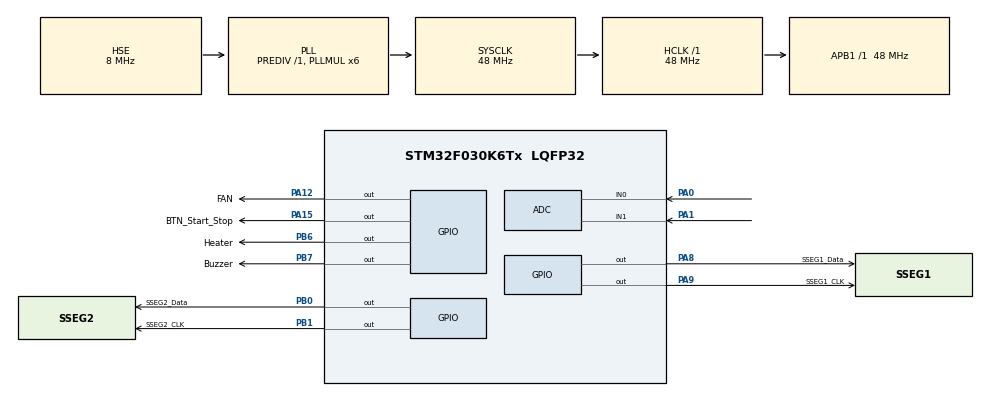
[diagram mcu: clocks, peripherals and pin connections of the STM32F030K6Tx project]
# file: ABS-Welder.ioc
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ADC.ContinuousConvMode=ENABLE
ADC.SamplingTime=ADC_SAMPLETIME_71CYCLES_5
Dma.ADC.0.Direction=DMA_PERIPH_TO_MEMORY
Dma.ADC.0.Instance=DMA1_Channel1
Dma.ADC.0.MemDataAlignment=DMA_MDATAALIGN_HALFWORD
Dma.ADC.0.MemInc=DMA_MINC_ENABLE
Dma.ADC.0.Mode=DMA_CIRCULAR
Dma.ADC.0.PeriphDataAlignment=DMA_PDATAALIGN_HALFWORD
Dma.ADC.0.PeriphInc=DMA_PINC_DISABLE
Dma.ADC.0.Priority=DMA_PRIORITY_MEDIUM
Dma.Request0=ADC
Mcu.Family=STM32F0
Mcu.Name=STM32F030K6Tx
Mcu.Package=LQFP32
NVIC.ADC1_IRQn=true\:0\:0\:false\:false\:true\:true\:true
NVIC.DMA1_Channel1_IRQn=true\:0\:0\:false\:false\:true\:false\:true
NVIC.TIM3_IRQn=true\:3\:0\:false\:false\:true\:false\:true
NVIC.TimeBase=TIM3_IRQn
NVIC.TimeBaseIP=TIM3
PA0.Mode=IN0
PA0.Signal=ADC_IN0
PA1.Mode=IN1
PA1.Signal=ADC_IN1
PA12.GPIO_Label=FAN
PA12.Signal=GPIO_Output
PA13.Mode=Serial_Wire
PA13.Signal=SYS_SWDIO
PA14.Mode=Serial_Wire
PA14.Signal=SYS_SWCLK
PA15.GPIO_Label=BTN_Start_Stop
PA15.Signal=GPIO_Output
PA8.GPIO_Label=SSEG1_Data
PA8.Signal=GPIO_Output
PA9.GPIO_Label=SSEG1_CLK
PA9.Signal=GPIO_Output
PB0.GPIO_Label=SSEG2_Data
PB0.Signal=GPIO_Output
PB1.GPIO_Label=SSEG2_CLK
PB1.Signal=GPIO_Output
PB6.GPIO_Label=Heater
PB6.Signal=GPIO_Output
PB7.GPIO_Label=Buzzer
PB7.Signal=GPIO_Output
PF0-OSC_IN.Mode=HSE-External-Oscillator
PF0-OSC_IN.Signal=RCC_OSC_IN
PF1-OSC_OUT.Mode=HSE-External-Oscillator
PF1-OSC_OUT.Signal=RCC_OSC_OUT
ProjectManager.HeapSize=0x200
ProjectManager.StackSize=0x400
ProjectManager.TargetToolchain=STM32CubeIDE
RCC.AHBFreq_Value=48000000
RCC.APB1Freq_Value=48000000
RCC.APB1TimFreq_Value=48000000
RCC.HCLKFreq_Value=48000000
RCC.PLLMUL=RCC_PLL_MUL6
RCC.PLLSourceVirtual=RCC_PLLSOURCE_HSE
RCC.SYSCLKFreq_VALUE=48000000
RCC.SYSCLKSource=RCC_SYSCLKSOURCE_PLLCLK
VP_ADC_TempSens_Input.Mode=IN-TempSens
VP_SYS_VS_tim3.Mode=TIM3
board=custom

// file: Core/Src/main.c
/* USER CODE BEGIN Header */
/**
  ******************************************************************************
  * @file           : main.c
  * @brief          : Main program body
  ******************************************************************************
  * @attention
  *
  * Copyright (c) 2021 STMicroelectronics.
  * All rights reserved.
  *
  * This software is licensed under terms that can be found in the LICENSE file
  * in the root directory of this software component.
  * If no LICENSE file comes with this software, it is provided AS-IS.
  *
  ******************************************************************************
  */
/* USER CODE END Header */
#include "main.h"
#include "adc.h"
#include "dma.h"
#include "gpio.h"

/* USER CODE BEGIN Includes */
#include "stm32_tm1637.h"
#include "../../Drivers/ABS-Welder-libs/ABS-Welder-lib.h"
/* USER CODE END Includes */

/* USER CODE BEGIN PV */
TM1637_structure top_7seg_struct = {.CLK_GPIO = SSEG1_CLK_GPIO_Port , .CLK_Pin = SSEG1_CLK_Pin
, .Data_GPIO = SSEG1_Data_GPIO_Port , .Data_Pin = SSEG1_Data_Pin};
TM1637_structure bottom_7seg_struct = {.CLK_GPIO = SSEG2_CLK_GPIO_Port , .CLK_Pin = SSEG2_CLK_Pin
	, .Data_GPIO = SSEG2_Data_GPIO_Port , .Data_Pin = SSEG2_Data_Pin};
/* USER CODE END PV */

void SystemClock_Config(void);

int main(void)
{

  /* MCU Configuration--------------------------------------------------------*/

  /* Reset of all peripherals, Initializes the Flash interface and the Systick. */
  HAL_Init();

  /* Configure the system clock */
  SystemClock_Config();

  /* Initialize all configured peripherals */
  MX_GPIO_Init();
  MX_ADC_Init();
  MX_DMA_Init();
  /* USER CODE BEGIN 2 */
  tm1637Init(top_7seg_struct);
  tm1637SetBrightness(top_7seg_struct, 8);
  tm1637Init(bottom_7seg_struct);
  tm1637SetBrightness(bottom_7seg_struct, 8);
  /* USER CODE END 2 */

  /* Infinite loop */
  while (1)
  {

  }
}

void SystemClock_Config(void)
{
  RCC_OscInitTypeDef RCC_OscInitStruct = {0};
  RCC_ClkInitTypeDef RCC_ClkInitStruct = {0};

  /** Initializes the RCC Oscillators according to the specified parameters
  * in the RCC_OscInitTypeDef structure.
  */
  RCC_OscInitStruct.OscillatorType = RCC_OSCILLATORTYPE_HSI14|RCC_OSCILLATORTYPE_HSE;
  RCC_OscInitStruct.HSEState = RCC_HSE_ON;
  RCC_OscInitStruct.HSI14State = RCC_HSI14_ON;
  RCC_OscInitStruct.HSI14CalibrationValue = 16;
  RCC_OscInitStruct.PLL.PLLState = RCC_PLL_ON;
  RCC_OscInitStruct.PLL.PLLSource = RCC_PLLSOURCE_HSE;
  RCC_OscInitStruct.PLL.PLLMUL = RCC_PLL_MUL6;
  RCC_OscInitStruct.PLL.PREDIV = RCC_PREDIV_DIV1;
  if (HAL_RCC_OscConfig(&RCC_OscInitStruct) != HAL_OK)
  {
    Error_Handler();
  }
  /** Initializes the CPU, AHB and APB buses clocks
  */
  RCC_ClkInitStruct.ClockType = RCC_CLOCKTYPE_HCLK|RCC_CLOCKTYPE_SYSCLK
                              |RCC_CLOCKTYPE_PCLK1;
  RCC_ClkInitStruct.SYSCLKSource = RCC_SYSCLKSOURCE_PLLCLK;
  RCC_ClkInitStruct.AHBCLKDivider = RCC_SYSCLK_DIV1;
  RCC_ClkInitStruct.APB1CLKDivider = RCC_HCLK_DIV1;

  if (HAL_RCC_ClockConfig(&RCC_ClkInitStruct, FLASH_LATENCY_1) != HAL_OK)
  {
    Error_Handler();
  }
}

void HAL_TIM_PeriodElapsedCallback(TIM_HandleTypeDef *htim)
{
  if (htim->Instance == TIM3) {
    HAL_IncTick();
  }
}

void Error_Handler(void)
{
  __disable_irq();
  while (1)
  {
  }
}
